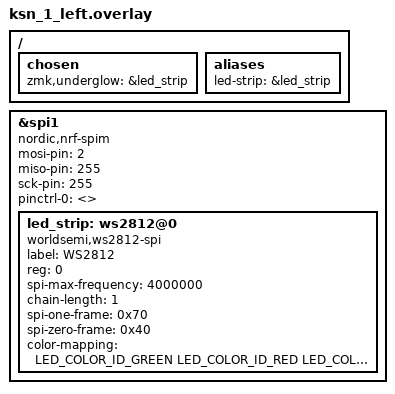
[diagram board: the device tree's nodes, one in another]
/*
 * ksn_1_left.overlay — 마스터(왼쪽) 전용
 *
 * SK6812 CapsLock RGB LED
 * D19 = P0.02 → SPI1 MOSI
 */

#include "ksn_1.dtsi"

/ {
    chosen {
        zmk,underglow = &led_strip;
    };

    aliases {
        led-strip = &led_strip;
    };
};

&spi1 {
    compatible    = "nordic,nrf-spim";
    status        = "okay";
    mosi-pin      = <2>;     /* D19 = P0.02 = CapsLock SK6812 DIN */
    miso-pin      = <255>;
    sck-pin       = <255>;
    pinctrl-0     = <>;
    pinctrl-names = "default";

    led_strip: ws2812@0 {
        compatible        = "worldsemi,ws2812-spi";
        label             = "WS2812";
        reg               = <0>;
        spi-max-frequency = <4000000>;
        chain-length      = <1>;
        spi-one-frame     = <0x70>;
        spi-zero-frame    = <0x40>;
        color-mapping     = <LED_COLOR_ID_GREEN
                             LED_COLOR_ID_RED
                             LED_COLOR_ID_BLUE>;
    };
};
